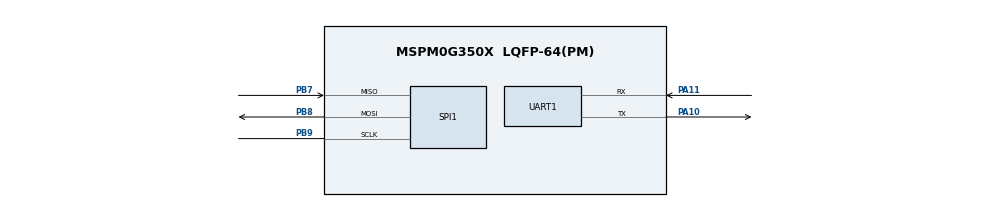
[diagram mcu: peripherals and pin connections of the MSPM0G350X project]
/**
 * @cliArgs --device "MSPM0G350X" --part "Default" --package "LQFP-64(PM)" --product "mspm0_sdk@2.05.01.01"
 * @versions {"tool":"1.24.0+4150"}
 */

/**
 * Import the modules used in this configuration.
 */
const GPIO   = scripting.addModule("/ti/driverlib/GPIO", {}, false);
const GPIO1  = GPIO.addInstance();
const SPI    = scripting.addModule("/ti/driverlib/SPI", {}, false);
const SPI1   = SPI.addInstance();
const SYSCTL = scripting.addModule("/ti/driverlib/SYSCTL");
const TIMER  = scripting.addModule("/ti/driverlib/TIMER", {}, false);
const TIMER1 = TIMER.addInstance();
const UART   = scripting.addModule("/ti/driverlib/UART", {}, false);
const UART1  = UART.addInstance();

/**
 * Write custom configuration values to the imported modules.
 */
const gate7  = system.clockTree["MFCLKGATE"];
gate7.enable = true;

GPIO1.$name                          = "CS";
GPIO1.associatedPins[0].assignedPort = "PORTB";
GPIO1.associatedPins[0].assignedPin  = "6";
GPIO1.associatedPins[0].$name        = "PIN";

const Board = scripting.addModule("/ti/driverlib/Board", {}, false);

SPI1.polarity                           = "1";
SPI1.phase                              = "1";
SPI1.targetBitRate                      = 2000000;
SPI1.$name                              = "SPI";
SPI1.frameFormat                        = "MOTO3";
SPI1.sclkPinConfig.$name                = "ti_driverlib_gpio_GPIOPinGeneric0";
SPI1.sclkPinConfig.direction            = scripting.forceWrite("OUTPUT");
SPI1.sclkPinConfig.onlyInternalResistor = scripting.forceWrite(false);
SPI1.sclkPinConfig.passedPeripheralType = scripting.forceWrite("Digital");
SPI1.mosiPinConfig.$name                = "ti_driverlib_gpio_GPIOPinGeneric1";
SPI1.mosiPinConfig.direction            = scripting.forceWrite("OUTPUT");
SPI1.mosiPinConfig.hideOutputInversion  = scripting.forceWrite(false);
SPI1.mosiPinConfig.onlyInternalResistor = scripting.forceWrite(false);
SPI1.mosiPinConfig.passedPeripheralType = scripting.forceWrite("Digital");
SPI1.misoPinConfig.$name                = "ti_driverlib_gpio_GPIOPinGeneric2";
SPI1.misoPinConfig.onlyInternalResistor = scripting.forceWrite(false);
SPI1.misoPinConfig.passedPeripheralType = scripting.forceWrite("Digital");
SPI1.peripheral.$assign                 = "SPI1";
SPI1.peripheral.sclkPin.$assign         = "PB9";
SPI1.peripheral.mosiPin.$assign         = "PB8";
SPI1.peripheral.misoPin.$assign         = "PB7";

SYSCTL.forceDefaultClkConfig = true;
SYSCTL.clockTreeEn           = true;

TIMER1.$name              = "TIMER_0";
TIMER1.timerMode          = "PERIODIC";
TIMER1.timerPeriod        = "20 ms";
TIMER1.timerClkPrescale   = 100;
TIMER1.timerStartTimer    = true;
TIMER1.interrupts         = ["ZERO"];
TIMER1.timerClkDiv        = 8;
TIMER1.peripheral.$assign = "TIMG0";

UART1.$name                    = "UART_0";
UART1.uartClkSrc               = "MFCLK";
UART1.targetBaudRate           = 115200;
UART1.peripheral.$assign       = "UART0";
UART1.peripheral.rxPin.$assign = "PA11";
UART1.peripheral.txPin.$assign = "PA10";
UART1.txPinConfig.$name        = "ti_driverlib_gpio_GPIOPinGeneric4";
UART1.rxPinConfig.$name        = "ti_driverlib_gpio_GPIOPinGeneric5";

/**
 * Pinmux solution for unlocked pins/peripherals. This ensures that minor changes to the automatic solver in a future
 * version of the tool will not impact the pinmux you originally saw.  These lines can be completely deleted in order to
 * re-solve from scratch.
 */
GPIO1.associatedPins[0].pin.$suggestSolution = "PB6";
Board.peripheral.$suggestSolution            = "DEBUGSS";
Board.peripheral.swclkPin.$suggestSolution   = "PA20";
Board.peripheral.swdioPin.$suggestSolution   = "PA19";
